# M4KL register map
File version: 0.1
Registers are 32-bit, read-write, reset 0x0 unless marked. A register's access mark holds for its fields unless they carry their own. Offsets are from the block's base; [hi:lo] are bit positions; {n}, {i} and the like mark numbered series.

## PJ — Port J
Base 0x400E0800
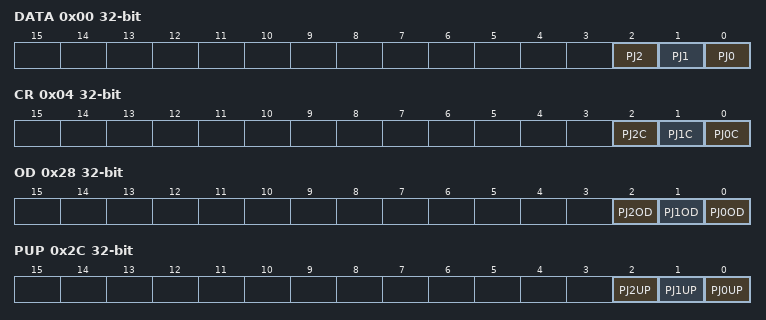
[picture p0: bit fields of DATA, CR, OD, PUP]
0x00 DATA — Port J Data Register
  [2] PJ2, [1] PJ1, [0] PJ0
0x04 CR — Port J Output Control Register
  [2] PJ2C, [1] PJ1C, [0] PJ0C
0x28 OD — Port J Open Drain Control Register
  [2] PJ2OD, [1] PJ1OD, [0] PJ0OD
0x2C PUP — Port J Pull-up Control Register
  [2] PJ2UP, [1] PJ1UP, [0] PJ0UP
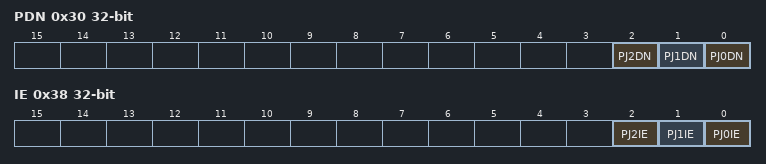
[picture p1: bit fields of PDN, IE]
0x30 PDN — Port J Pull-down Control Register
  [2] PJ2DN, [1] PJ1DN, [0] PJ0DN
0x38 IE — Port J Input Control Register
  [2] PJ2IE, [1] PJ1IE, [0] PJ0IE

## PK — Port K
Base 0x400E0900
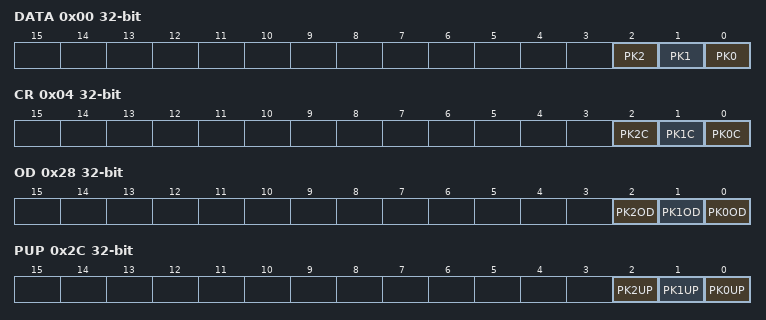
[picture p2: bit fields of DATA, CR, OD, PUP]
0x00 DATA — Port K Data Register
  [2] PK2, [1] PK1, [0] PK0
0x04 CR — Port K Output Control Register
  [2] PK2C, [1] PK1C, [0] PK0C
0x28 OD — Port K Open Drain Control Register
  [2] PK2OD, [1] PK1OD, [0] PK0OD
0x2C PUP — Port K Pull-up Control Register
  [2] PK2UP, [1] PK1UP, [0] PK0UP
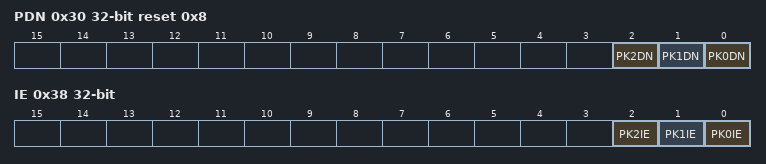
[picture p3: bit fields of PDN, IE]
0x30 PDN reset 0x8 — Port K Pull-down Control Register
  [2] PK2DN, [1] PK1DN, [0] PK0DN
0x38 IE — Port K Input Control Register
  [2] PK2IE, [1] PK1IE, [0] PK0IE

## PL — Port L
Base 0x400E0A00
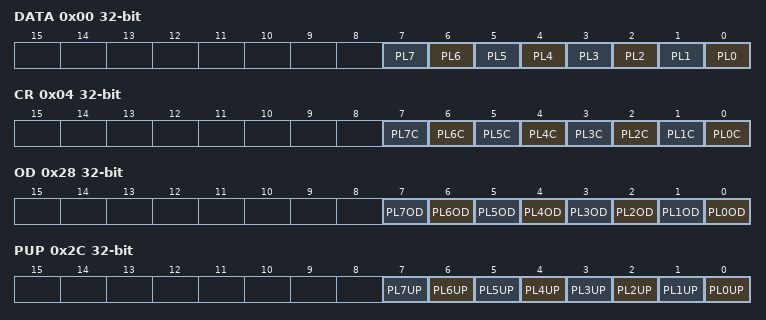
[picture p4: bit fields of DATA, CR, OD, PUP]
0x00 DATA — Port L Data Register
  [n] PL{n} (n=0..7)
0x04 CR — Port L Output Control Register
  [n] PL{n}C (n=0..7)
0x28 OD — Port L Open Drain Control Register
  [n] PL{n}OD (n=0..7)
0x2C PUP — Port L Pull-up Control Register
  [n] PL{n}UP (n=0..7)
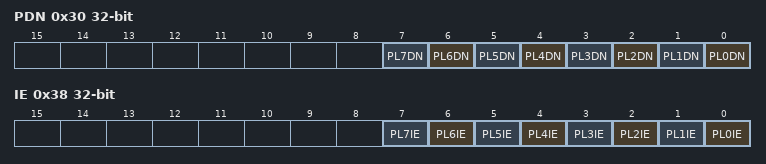
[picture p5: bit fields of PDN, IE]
0x30 PDN — Port L Pull-down Control Register
  [n] PL{n}DN (n=0..7)
0x38 IE — Port L Input Control Register
  [n] PL{n}IE (n=0..7)

## PU — Port U
Base 0x400E1000
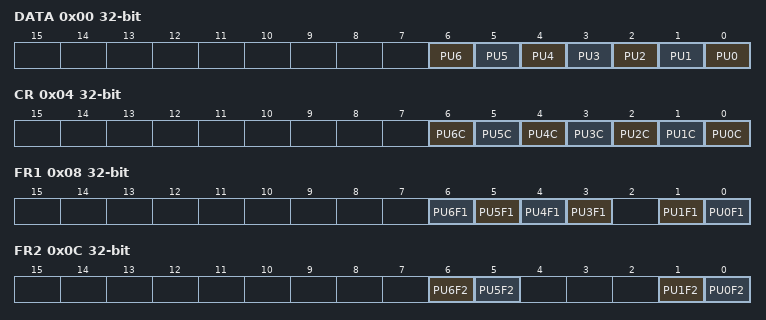
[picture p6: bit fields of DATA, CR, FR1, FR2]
0x00 DATA — Port U Data Register
  [n] PU{n} (n=0..6)
0x04 CR — Port U Output Control Register
  [n] PU{n}C (n=0..6)
0x08 FR1 — Port U Function Register 1
  [n] PU{n}F1 (n=3..6), [1] PU1F1, [0] PU0F1
0x0C FR2 — Port U Function Register 2
  [6] PU6F2, [5] PU5F2, [1] PU1F2, [0] PU0F2
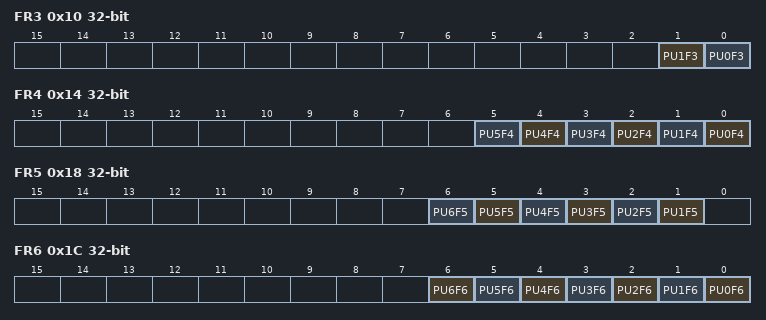
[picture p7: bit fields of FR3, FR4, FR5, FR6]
0x10 FR3 — Port U Function Register 3
  [1] PU1F3, [0] PU0F3
0x14 FR4 — Port U Function Register 4
  [n] PU{n}F4 (n=0..5)
0x18 FR5 — Port U Function Register 5
  [n] PU{n}F5 (n=1..6)
0x1C FR6 — Port U Function Register 6
  [n] PU{n}F6 (n=0..6)
0x20 FR7 — Port U Function Register 7
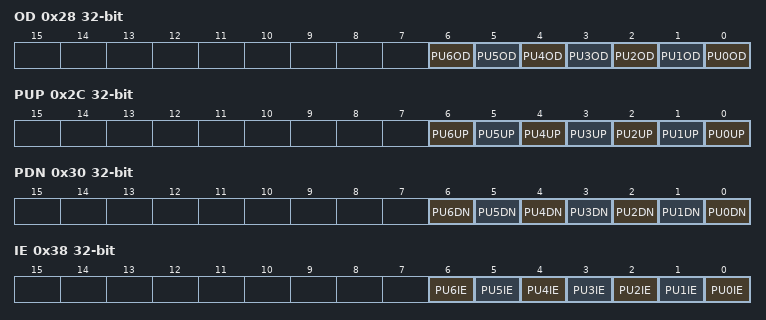
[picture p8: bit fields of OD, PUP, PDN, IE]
0x28 OD — Port U Open Drain Control Register
  [n] PU{n}OD (n=0..6)
0x2C PUP — Port U Pull-up Control Register
  [n] PU{n}UP (n=0..6)
0x30 PDN — Port U Pull-down Control Register
  [n] PU{n}DN (n=0..6)
0x38 IE — Port U Input Control Register
  [n] PU{n}IE (n=0..6)

## TRM — Trimming Circuit (TRM)
Base 0x400E3100
0x00 OSCPRO — Protection Register
  [7:0] PROTECT
0x04 OSCEN — TRM Enable Register
  [0] TRIMEN
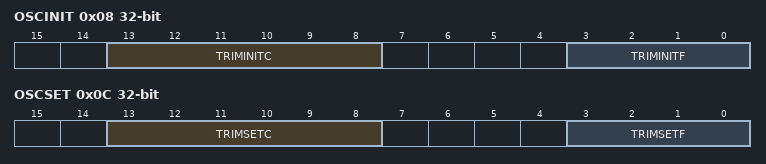
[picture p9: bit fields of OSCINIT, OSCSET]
0x08 OSCINIT ro (reset mask 0xFFFFC0F0) — TRM Initial Trimming Level Monitor Register
  [13:8] TRIMINITC, [3:0] TRIMINITF
0x0C OSCSET — TRM Trimming Level Setting Register
  [13:8] TRIMSETC, [3:0] TRIMSETF

## OFD — Oscillation Frequency Detector (OFD)
Base 0x400E4000
0x00 CR1 reset 0x6 — OFD Control Register 1
  [7:0] OFDWEN
0x04 CR2 — OFD Control Register 2
  [7:0] OFDEN
0x08 MN0 — OFD Lower Detection Frequency Setting Register0
  [11:0] OFDMN0
0x0C MN1 — OFD Lower Detection Frequency Setting Register1
  [11:0] OFDMN1
0x10 MX0 — OFD Higher Detection Frequency Setting Register0
  [11:0] OFDMX0
0x14 MX1 — OFD Higher Detection Frequency Setting Register1
  [11:0] OFDMX1
0x18 RST reset 0x1 — OFD Reset Enable Control Register
  [0] OFDRSTEN
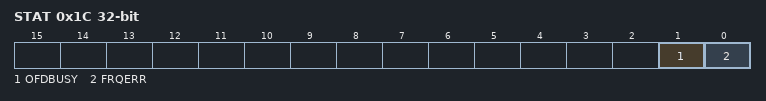
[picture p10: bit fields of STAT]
0x1C STAT ro — OFD Status Register
  [1] OFDBUSY, [0] FRQERR
0x20 MON reset 0x1 — OFD External high frequency oscillaion clock monitor register
  [0] OFDMON

## PMD0 — Advanced Progammable Motor Control Circuit (A-PMD)
Base 0x400E9000
Same registers: PMD1 0x400E9400, PMD2 0x400E9800
0x00 MDEN — PMD Enable Register
  [0] PWMEN
0x04 PORTMD — PMD Port Output Mode Register
  [1:0] PORTMD
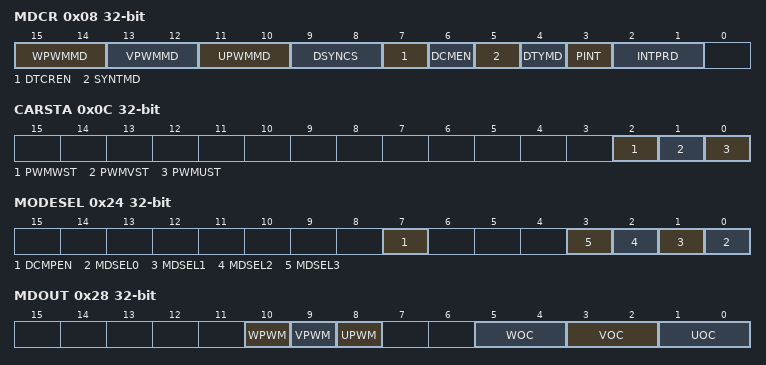
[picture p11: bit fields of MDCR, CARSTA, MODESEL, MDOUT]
0x08 MDCR — PMD Control Register
  [15:14] WPWMMD, [13:12] VPWMMD, [11:10] UPWMMD, [9:8] DSYNCS, [7] DTCREN, [6] DCMEN, [5] SYNTMD, [4] DTYMD, [3] PINT, [2:1] INTPRD
0x0C CARSTA ro — PWM Carrier Status Register
  [2] PWMWST, [1] PWMVST, [0] PWMUST
0x10 BCARI ro — PWM Basic Carrier Register
  [14:0] BCARI
0x14 RATE — PWM Frequency Register
  [14:0] RATE
0x18 CMPU — PMD PWM Compare U Register
  [15:0] CMPU
0x1C CMPV — PMD PWM Compare V Register
  [15:0] CMPV
0x20 CMPW — PMD PWM Compare W Register
  [15:0] CMPW
0x24 MODESEL — PMD Mode Select Register
  [7] DCMPEN, [n] MDSEL{n} (n=0..3)
0x28 MDOUT — PMD Conduction Control Register
  [10] WPWM, [9] VPWM, [8] UPWM, [5:4] WOC, [3:2] VOC, [1:0] UOC
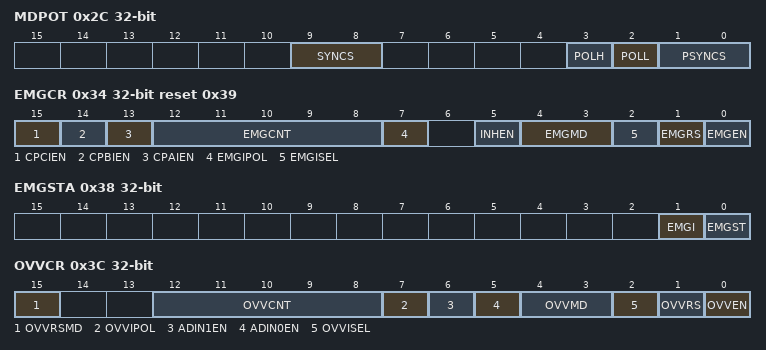
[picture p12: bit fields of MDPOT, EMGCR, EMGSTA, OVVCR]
0x2C MDPOT — PMD Output Setting Register
  [9:8] SYNCS, [3] POLH, [2] POLL, [1:0] PSYNCS
0x30 EMGREL wo — PMD EMG Release Register
  [7:0] EMGREL
0x34 EMGCR reset 0x39 — PMD EMG Control Register
  [15] CPCIEN, [14] CPBIEN, [13] CPAIEN, [12:8] EMGCNT, [7] EMGIPOL, [5] INHEN, [4:3] EMGMD, [2] EMGISEL, [1] EMGRS wo, [0] EMGEN
0x38 EMGSTA ro (reset mask 0xFFFFFFFD) — PMD EMG Status Register
  [1] EMGI, [0] EMGST
0x3C OVVCR — PMD OVV Control Register
  [15] OVVRSMD, [12:8] OVVCNT, [7] OVVIPOL, [6] ADIN1EN, [5] ADIN0EN, [4:3] OVVMD, [2] OVVISEL, [1] OVVRS wo, [0] OVVEN
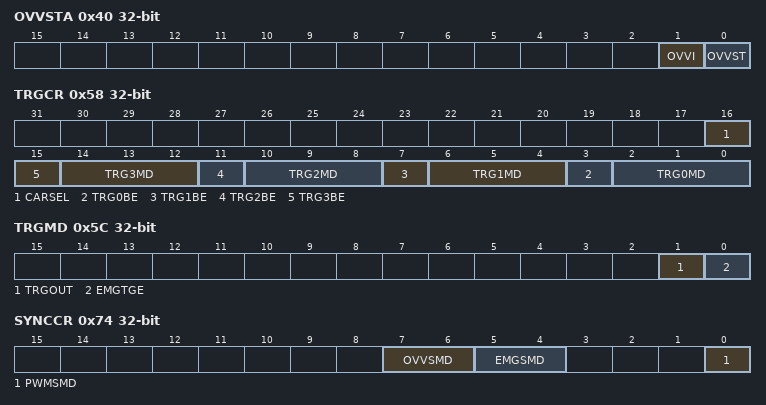
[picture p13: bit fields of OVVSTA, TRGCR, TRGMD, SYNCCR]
0x40 OVVSTA ro (reset mask 0xFFFFFFFD) — PMD OVV Status Register
  [1] OVVI, [0] OVVST
0x44 DTR — PMD Dead Time Register
  [9:0] DTR
{0x48+4i} TRGCMP{i} (i=0..3) — PMD Trigger Compare Register {i}
  [14:0] TRGCMP{i}
0x58 TRGCR — PMD Trigger Control Register
  [16] CARSEL, [4n+3] TRG{n}BE (n=0..3), [4n+2:4n] TRG{n}MD (n=0..3)
0x5C TRGMD — PMD Trigger Output Mode Setting Register
  [1] TRGOUT, [0] EMGTGE
0x60 TRGSEL — PMD Trigger Output Select Register
  [2:0] TRGSEL
0x64 TRGSYNCR — PMD Trigger Update Timing Setting Register
  [1:0] TSYNCS
0x68 VPWMPH — PMD Phase difference setting of the V-phase PWM
  [14:0] VPWMPH
0x6C WPWMPH — PMD Phase difference setting of the W-phase PWM
  [14:0] WPWMPH
0x70 MBUFCR — PMD Update timing of the triple buffer
  [2:0] BUFCTR
0x74 SYNCCR — PMD Synchronization control between the PMD channel
  [7:6] OVVSMD, [5:4] EMGSMD, [0] PWMSMD
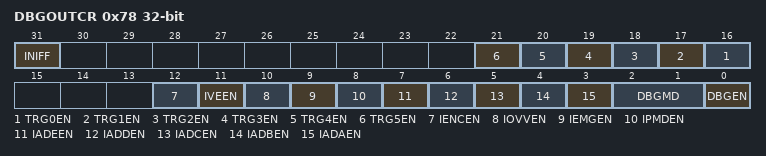
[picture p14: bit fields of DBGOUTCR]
0x78 DBGOUTCR — PMD Debug output control
  [31] INIFF, [n+16] TRG{n}EN (n=0..5), [12] IENCEN, [11] IVEEN, [10] IOVVEN, [9] IEMGEN, [8] IPMDEN, [7] IADEEN, [6] IADDEN, [5] IADCEN, [4] IADBEN, [3] IADAEN, [2:1] DBGMD, [0] DBGEN

## EN — Advanced Encoder Input (A-ENC32)
Base 0x400EA800
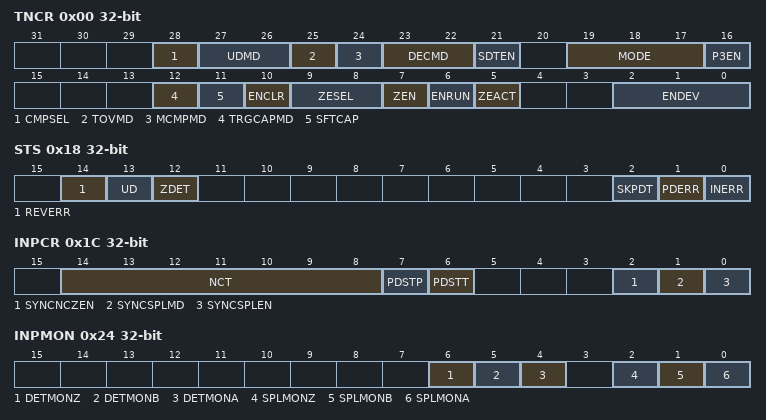
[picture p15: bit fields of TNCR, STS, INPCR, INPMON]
0x00 TNCR — ENC Control Register
  [28] CMPSEL, [27:26] UDMD, [25] TOVMD, [24] MCMPMD, [23:22] DECMD, [21] SDTEN, [19:17] MODE, [16] P3EN, [12] TRGCAPMD, [11] SFTCAP wo, [10] ENCLR wo, [9:8] ZESEL, [7] ZEN, [6] ENRUN, [5] ZEACT, [2:0] ENDEV
0x04 RELOAD — ENC Reload Compare Register
0x08 INT — ENC INT Compare Register
0x0C CNT ro — ENC Counter_Capture Register
0x10 MCMP — ENC MCMP Compare Register
0x14 RATE — ENC Phase Count Rate Register
  [15:0] RATE
0x18 STS ro — ENC Status Register
  [14] REVERR, [13] UD, [12] ZDET, [2] SKPDT, [1] PDERR, [0] INERR
0x1C INPCR — ENC Input Process Cntrol Register
  [14:8] NCT, [7] PDSTP wo, [6] PDSTT wo, [2] SYNCNCZEN, [1] SYNCSPLMD, [0] SYNCSPLEN
0x20 SMPDLY — ENC Sample Delay Register
  [7:0] SMPDLY
0x24 INPMON ro — ENC Input Moniter Register
  [6] DETMONZ, [5] DETMONB, [4] DETMONA, [2] SPLMONZ, [1] SPLMONB, [0] SPLMONA
0x28 CLKCR — ENC Sample Clock Control Register
  [1:0] SPLCKS
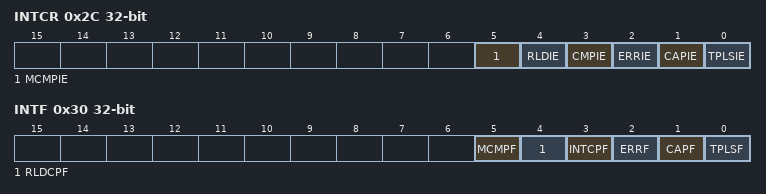
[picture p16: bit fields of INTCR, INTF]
0x2C INTCR — ENC Interrupt Control Register
  [5] MCMPIE, [4] RLDIE, [3] CMPIE, [2] ERRIE, [1] CAPIE, [0] TPLSIE
0x30 INTF ro — ENC Interrupt Event Flag Register
  [5] MCMPF, [4] RLDCPF, [3] INTCPF, [2] ERRF, [1] CAPF, [0] TPLSF

## FC — Flash Memory Interface (FC)
Base 0x5DFF0000
0x10 SBMR reset 0x1 — Flash Security Bit Mask Register
  [0] SMB
0x14 SSR ro (reset mask 0xFFFFFFFE) — Flash Security Status Register
  [0] SEC
0x18 KCR wo — Flash Key Code Register
  [31:0] KEYCODE
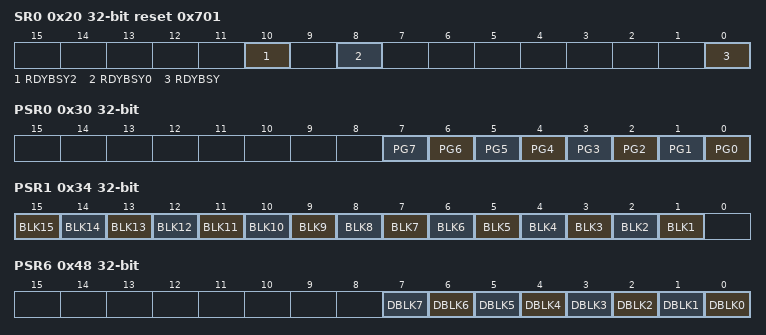
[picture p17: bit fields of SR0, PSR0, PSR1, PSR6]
0x20 SR0 ro reset 0x701 — Flash Status Register 0
  [10] RDYBSY2, [8] RDYBSY0, [0] RDYBSY
0x30 PSR0 ro (reset mask 0xFFFFFF00) — Flash Protect Status Register 0
  [n] PG{n} (n=0..7)
0x34 PSR1 ro (reset mask 0xFFFF0001) — Flash Protect Status Register 1
  [n] BLK{n} (n=1..15)
0x48 PSR6 ro (reset mask 0xFFFFFF00) — Flash Protect Status Register 6
  [n] DBLK{n} (n=0..7)
0x50 PMR0 reset 0xFF — Flash Protect Mask Register 0
  [n] PM{n} (n=0..7)
0x54 PMR1 reset 0xFFFFFFFE — Flash Protect Mask Register 1
  [n] MSK{n} (n=1..15)
0x68 PMR6 reset 0xFFFE — Flash Protect Mask Register 6
  [n] DMSK{n} (n=0..7)
0x100 SR1 ro — Flash Status Register 1
  [24] WEABORT
0x104 SWPSR ro — Flash Memory SWAP Status Register
  [13:8] SIZE, [1:0] SWP
0x140 AREASEL — Flash Area Selection Register
  [30] SSF4 ro, [26] SSF0 ro, [18:16] AREA4, [2:0] AREA0
0x148 CR — Flash Control Register
  [2:0] WEABORT
0x14C STSCLR — Flash Status Clear Register
  [2:0] WEABORT
0x150 BNKCR — Flash Bank Change Register
  [2:0] BANK0
0x158 BUFDISCLR — Flash Buffer Disable and Clear Register
  [2:0] BUFDISCLR
